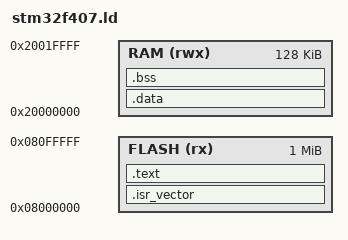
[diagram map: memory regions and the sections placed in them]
/* Linker script — STM32F407VG: 1MB Flash, 192KB RAM */
MEMORY
{
    FLASH (rx)  : ORIGIN = 0x08000000, LENGTH = 1024K
    RAM   (rwx) : ORIGIN = 0x20000000, LENGTH = 128K
}

_estack = ORIGIN(RAM) + LENGTH(RAM);

SECTIONS
{
    .isr_vector :
    {
        KEEP(*(.isr_vector))
    } > FLASH

    .text :
    {
        *(.text*)
        *(.rodata*)
        _sidata = .;
    } > FLASH

    .data : AT(_sidata)
    {
        _sdata = .;
        *(.data*)
        _edata = .;
    } > RAM

    .bss :
    {
        _sbss = .;
        *(.bss*)
        *(COMMON)
        _ebss = .;
    } > RAM

    /DISCARD/ : { *(.eh_frame) }
}
